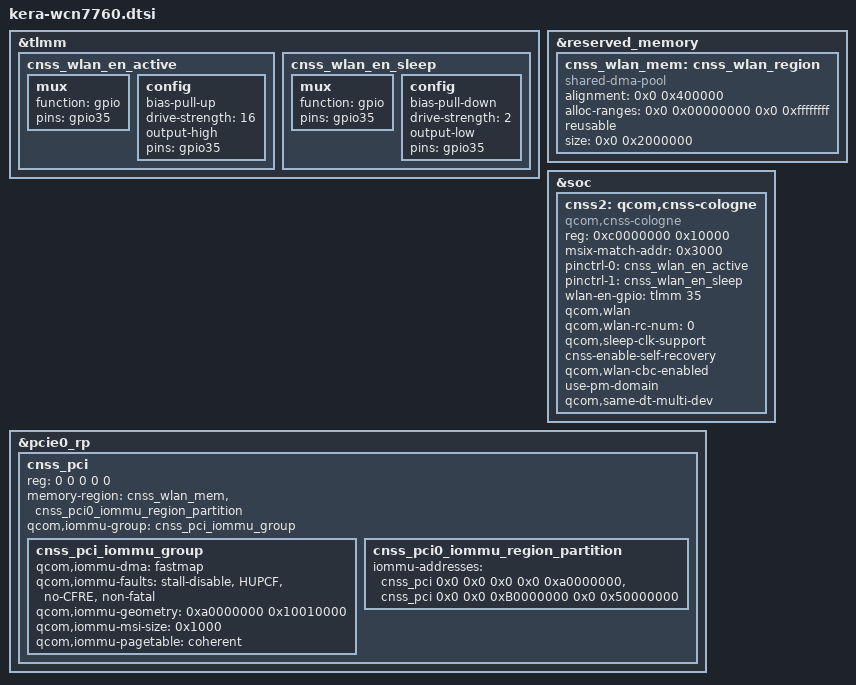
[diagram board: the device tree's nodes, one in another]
// SPDX-License-Identifier: BSD-3-Clause

/*
 * Copyright (c) Qualcomm Technologies, Inc. and/or its subsidiaries.
 */

#include <dt-bindings/interrupt-controller/arm-gic.h>
#include <dt-bindings/interconnect/qcom,kera.h>

&tlmm {
	cnss_wlan_en_active: cnss_wlan_en_active {
		mux {
			function = "gpio";
			pins = "gpio35";
		};

		config {
			bias-pull-up;
			drive-strength = <16>;
			output-high;
			pins = "gpio35";
		};
	};

	cnss_wlan_en_sleep: cnss_wlan_en_sleep {
		mux {
			function = "gpio";
			pins = "gpio35";
		};

		config {
			bias-pull-down;
			drive-strength = <2>;
			output-low;
			pins = "gpio35";
		};
	};
};

&reserved_memory {
	cnss_wlan_mem: cnss_wlan_region {
		compatible = "shared-dma-pool";
		alignment = <0x0 0x400000>;
		alloc-ranges = <0x0 0x00000000 0x0 0xffffffff>;
		reusable;
		size = <0x0 0x2000000>;
	};
};

&soc {
	cnss2: qcom,cnss-cologne {
		compatible = "qcom,cnss-cologne";
		reg = <0xc0000000 0x10000>;
		reg-names = "smmu_iova_ipa";

		msix-match-addr = <0x3000>;
		pinctrl-names = "wlan_en_active", "wlan_en_sleep";
		pinctrl-0 = <&cnss_wlan_en_active>;
		pinctrl-1 = <&cnss_wlan_en_sleep>;
		wlan-en-gpio = <&tlmm 35 0>;

		qcom,wlan;
		qcom,wlan-rc-num = <0>;
		qcom,sleep-clk-support;
		cnss-enable-self-recovery;
		qcom,wlan-cbc-enabled;
		use-pm-domain;
		qcom,same-dt-multi-dev;
	};
};

&pcie0_rp {
	cnss_pci: cnss_pci {
		reg = <0 0 0 0 0>;

		memory-region = <&cnss_wlan_mem &cnss_pci0_iommu_region_partition>;
		qcom,iommu-group = <&cnss_pci_iommu_group>;

		#address-cells = <1>;
		#size-cells = <1>;

		cnss_pci_iommu_group: cnss_pci_iommu_group {
			qcom,iommu-dma = "fastmap";
			qcom,iommu-faults = "stall-disable", "HUPCF", "no-CFRE",
					    "non-fatal";
			qcom,iommu-geometry = <0xa0000000 0x10010000>;
			qcom,iommu-msi-size = <0x1000>;
			qcom,iommu-pagetable = "coherent";
		};

		cnss_pci0_iommu_region_partition: cnss_pci0_iommu_region_partition {
			iommu-addresses = <&cnss_pci 0x0 0x0 0x0 0x0 0xa0000000>,
					  <&cnss_pci 0x0 0x0 0xB0000000 0x0 0x50000000>;
		};
	};
};
